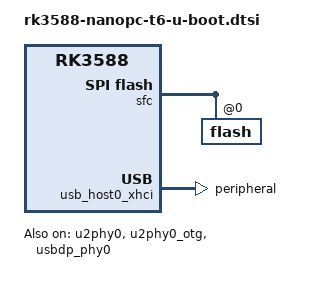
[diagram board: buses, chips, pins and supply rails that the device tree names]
// SPDX-License-Identifier: (GPL-2.0+ OR MIT)
/*
 * Copyright (c) 2023 John Clark <inindev@gmail.com>
 *
 */

#include "rk3588-u-boot.dtsi"

&fspim1_pins {
	bootph-pre-ram;
	bootph-some-ram;
};

&saradc {
	bootph-pre-ram;
	vdd-microvolts = <1800000>;
};

&sfc {
	flash@0 {
		bootph-pre-ram;
		bootph-some-ram;
	};
};

&u2phy0 {
	status = "okay";
};

&u2phy0_otg {
	status = "okay";
};

&usbdp_phy0 {
	status = "okay";
};

&usb_host0_xhci {
	dr_mode = "peripheral";
	maximum-speed = "high-speed";
	status = "okay";
};
